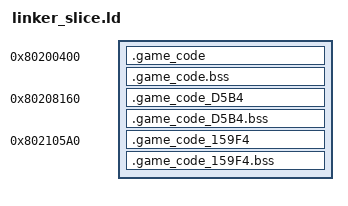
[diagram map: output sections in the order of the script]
/* generated from config.toml; do not edit */
OUTPUT_ARCH(mips)
SECTIONS
{
    .game_code 0x80200400 : AT(0x5854) SUBALIGN(1)
    {
        src/AI/DEVICES/ACTIONHIT/ACTIONHIT.CPP.o(.text);
        . = MAX(., 0x46C);
        src/AI/DEVICES/DAMAGEAI/DAMAGEAI.CPP.o(.text);
        . = MAX(., 0x8AC);
        src/AI/DEVICES/DEVICECALLBACK/DEVICECALLBACK.CPP.o(.text);
        . = MAX(., 0xAEC);
        src/AI/DEVICES/SPAWNAI/SPAWNAI.CPP.o(.text);
        . = MAX(., 0x144C);
        src/AI/DEVICES/MOVINGAI/MOVINGAI.CPP.o(.text);
        . = MAX(., 0x1B38);
        src/AI/DEVICES/MOVINGAI/TRIGGERED_UPDATETRIGGEREDMOTION.CPP.o(.text);
        . = MAX(., 0x2CDC);
        src/AI/DEVICES/PLAYERMATRIX/PLAYERMATRIX.CPP.o(.text);
        . = MAX(., 0x33C4);
        src/AI/DEVICES/ACTIONAI/LEVEL_UPDATEBREAKABLEHIT_PADDING.CPP.o(.data);
        . = MAX(., 0x33CC);
        src/AI/NAV/PLAYER/PLAYER.CPP.o(.text);
        . = MAX(., 0x49C4);
        src/AI/NAV/PLAYER/SCALED_UPDATETARGETPITCH.CPP.o(.text);
        . = MAX(., 0x524C);
        src/AI/NAV/PORTAL/PORTAL_UPDATEALTERNATINGACTIONBURSTS.CPP.o(.text);
        . = MAX(., 0x5DD8);
        src/AI/NAV/PORTAL/PORTAL.CPP.o(.text);
        . = MAX(., 0x6D28);
        src/AI/NAV/PORTAL/PORTAL_SEARCHPATH.CPP.o(.text);
    }
    .game_code.bss (NOLOAD) :
    {
        src/AI/DEVICES/ACTIONHIT/ACTIONHIT.CPP.o(.bss .sbss COMMON);
        src/AI/DEVICES/DAMAGEAI/DAMAGEAI.CPP.o(.bss .sbss COMMON);
        src/AI/DEVICES/DEVICECALLBACK/DEVICECALLBACK.CPP.o(.bss .sbss COMMON);
        src/AI/DEVICES/SPAWNAI/SPAWNAI.CPP.o(.bss .sbss COMMON);
        src/AI/DEVICES/MOVINGAI/MOVINGAI.CPP.o(.bss .sbss COMMON);
        src/AI/DEVICES/MOVINGAI/TRIGGERED_UPDATETRIGGEREDMOTION.CPP.o(.bss .sbss COMMON);
        src/AI/DEVICES/PLAYERMATRIX/PLAYERMATRIX.CPP.o(.bss .sbss COMMON);
        src/AI/DEVICES/ACTIONAI/LEVEL_UPDATEBREAKABLEHIT_PADDING.CPP.o(.bss .sbss COMMON);
        src/AI/NAV/PLAYER/PLAYER.CPP.o(.bss .sbss COMMON);
        src/AI/NAV/PLAYER/SCALED_UPDATETARGETPITCH.CPP.o(.bss .sbss COMMON);
        src/AI/NAV/PORTAL/PORTAL_UPDATEALTERNATINGACTIONBURSTS.CPP.o(.bss .sbss COMMON);
        src/AI/NAV/PORTAL/PORTAL.CPP.o(.bss .sbss COMMON);
        src/AI/NAV/PORTAL/PORTAL_SEARCHPATH.CPP.o(.bss .sbss COMMON);
    }
    .game_code_D5B4 0x80208160 : AT(0xD5B4) SUBALIGN(1)
    {
        src/AI/NAV/PORTAL/PORTAL_ISNODEMOVEMENTBLOCKED.CPP.o(.text);
        . = MAX(., 0x6DC);
        src/AI/NAV/ROUTE/ROUTE.CPP.o(.text);
        . = MAX(., 0x88C);
        src/AI/NAV/SEARCHNODE/SEARCHNODE.CPP.o(.text.Nav_AddGoalNode);
        . = MAX(., 0x8EC);
        src/AI/NAV/SEARCHNODE/SEARCHNODE.CPP.o(.text.Nav_OpenSearchNode);
        . = MAX(., 0x8F8);
        src/AI/NAV/SEARCHNODE/SEARCHNODE.CPP.o(.text.Nav_TakeLowestCostOpenNode);
        . = MAX(., 0x968);
        src/AI/NAV/SEARCHNODE/SEARCHNODE.CPP.o(.text.Nav_CloseSearchNode);
        . = MAX(., 0x974);
        src/AI/NAV/ROUTECOST/ROUTECOST.CPP.o(.text.Nav_IsSearchNodeOpen);
        . = MAX(., 0x984);
        src/AI/NAV/SEARCHNODE/SEARCHNODE.CPP.o(.text.Nav_IsSearchNodeClosed);
        . = MAX(., 0x994);
        src/AI/NAV/SEARCHNODE/SEARCHNODE.CPP.o(.text.Nav_HasOpenSearchNodes);
        . = MAX(., 0x9C8);
        src/AI/NAV/SEARCHNODE/SEARCHNODE.CPP.o(.text.Nav_ClearSearchNodeStatus);
        . = MAX(., 0x9D0);
        src/AI/DEVICES/ACTIONAI/ACTION_LINK_GAP_FRAGMENTS.CPP.o(.data);
        . = MAX(., 0x9DC);
        src/AI/NAV/PICKUP.CPP.o(.text);
        . = MAX(., 0x102C);
        src/AI/NAV/POINTS/POINTS.CPP.o(.text);
        . = MAX(., 0x1270);
        src/AI/DEVICES/PLAYER/DEVICE_BUILDPLAYERMATRIX/DEVICE_BUILDPLAYERMATRIX.CPP.o(.data);
        . = MAX(., 0x127C);
        src/AI/NAV/ATTACK/ATTACK.CPP.o(.text);
        . = MAX(., 0x130C);
        src/AI/NAV/RESELECT/RESELECT.CPP.o(.text);
        . = MAX(., 0x1440);
        src/AI/NAV/RESELECT/RESELECT.CPP.o(.data);
        . = MAX(., 0x144C);
        src/AI/NAV/BALLISTIC/BALLISTIC.CPP.o(.text);
        . = MAX(., 0x2070);
        src/AI/NAV/NAV/G_NAVTRAILINGBYTESBLOCK1.CPP.o(.data);
        . = MAX(., 0x207C);
        src/AI/NAV/TEAMMARKER/TEAMMARKER.CPP.o(.text);
        . = MAX(., 0x214C);
        src/AI/NAV/PICKUPGOAL/PICKUPGOAL.CPP.o(.text);
        . = MAX(., 0x23BC);
        src/AI/NAV/ROUTECOST/ROUTECOST.CPP.o(.text.Nav_UpdateRouteIntermediateGoal);
        . = MAX(., 0x2438);
        src/AI/NAV/ROUTECOST/ROUTECOST.CPP.o(.text.Nav_SetLinkedActorNodeCosts);
        . = MAX(., 0x24BC);
        src/AI/NAV/ROUTECOST/ROUTECOST.CPP.o(.text.Nav_AccumulateNodeTickCosts);
        . = MAX(., 0x2510);
        src/AI/NAV/ROUTECOST/ROUTECOST.CPP.o(.text.Nav_AddPickupCategoryCosts);
        . = MAX(., 0x25C0);
        src/AI/NAV/ROUTECOST/ROUTECOST.CPP.o(.data);
        . = MAX(., 0x25CC);
        src/AI/NAV/PICKUPSELECT/PICKUPSELECT.CPP.o(.text);
        . = MAX(., 0x27BC);
        src/AI/NAV/PICKUPTARGET/PICKUPTARGET.CPP.o(.text);
        . = MAX(., 0x2D24);
        src/AI/NAV/NAV/NAV_TRAILING_BYTES_EU_EU_X_US_US_REV1.CPP.o(.data);
        . = MAX(., 0x2D2C);
        src/AI/NAV/TARGET/TARGET.CPP.o(.text);
        . = MAX(., 0x307C);
        src/AI/NAV/PLAYERSTATE/PLAYERSTATE.CPP.o(.text);
        . = MAX(., 0x341C);
        src/AI/NAV/WEAPONSELECT/WEAPONSELECT.CPP.o(.text);
        . = MAX(., 0x374C);
        src/AI/NAV/RANDOMWEAPON/RANDOMWEAPON.CPP.o(.text);
        . = MAX(., 0x37E4);
        src/AI/NAV/NAV.CPP.o(.data);
        . = MAX(., 0x37EC);
        src/AI/NAV/CLOSEATTACK/CLOSEATTACK.CPP.o(.text);
        . = MAX(., 0x3894);
        src/AI/NAV/NAV_CHECKCLOSEATTACKROUTE/G_NAVCHECKCLOSEATTACKROUTETRAILINGBYTESBLOCK1.CPP.o(.data);
        . = MAX(., 0x389C);
        src/AI/NAV/ATTACKTARGET/ATTACKTARGET.CPP.o(.text);
        . = MAX(., 0x3D48);
        src/DATA/MAINCODE/MAINCODE.CPP.o(.data);
        . = MAX(., 0x3D4C);
        src/AI/NAV/WHEEL/WHEEL.CPP.o(.text);
        . = MAX(., 0x4680);
        src/AI/NAV/NAV_INIT/NAV_INIT.CPP.o(.data);
        . = MAX(., 0x468C);
        src/AI/NAV/BEHAVIOUR/BEHAVIOUR.CPP.o(.text);
        . = MAX(., 0x4788);
        src/AI/NAV/BEHAVIOUR/BEHAVIOUR.CPP.o(.data);
        . = MAX(., 0x478C);
        src/AI/NAV/STRAFE/STRAFE.CPP.o(.text);
        . = MAX(., 0x4ADC);
        src/AI/NAV/COMBAT/COMBAT.CPP.o(.text);
        . = MAX(., 0x5ABC);
        src/AI/NAV/COMBATINIT/COMBATINIT.CPP.o(.text);
        . = MAX(., 0x5CD0);
        src/AI/NAV/ATTACK_TARGET/NAV/G_NAVTRAILINGBYTESBLOCK8.CPP.o(.data);
        . = MAX(., 0x5CDC);
        src/AI/NAV/FARTHEST/FARTHEST.CPP.o(.text);
        . = MAX(., 0x62FC);
        src/AI/NAV/CARRIER/CARRIER.CPP.o(.text);
        . = MAX(., 0x63C4);
        src/AI/NAV/CARRIER/CARRIER.CPP.o(.data);
        . = MAX(., 0x63CC);
        src/AI/NAV/TARGETFOLLOW/TARGETFOLLOW.CPP.o(.text);
        . = MAX(., 0x6470);
        src/AI/NAV/NAV/NAV_ENCODED_WORDS_EU.CPP.o(.data);
        . = MAX(., 0x647C);
        src/AI/NAV/PATROL/PATROL.CPP.o(.text);
        . = MAX(., 0x6640);
        src/AI/NAV/PATROL/PATROL.CPP.o(.data);
        . = MAX(., 0x664C);
        src/AI/NAV/OBJECTCHASE/NAV_UPDATEOBJECTARRIVALCHASE.CPP.o(.text);
        . = MAX(., 0x6844);
        src/AI/NAV/OBJECTCHASE/NAV_UPDATEOBJECTARRIVALCHASE.CPP.o(.data);
        . = MAX(., 0x684C);
        src/AI/NAV/JUMPROUTE/JUMPROUTE.CPP.o(.text);
        . = MAX(., 0x69A8);
        src/AI/NAV/WHEEL/NAV/WHEEL_TRAILING_BYTES_EU_EU_X_US_US_REV1.CPP.o(.data);
        . = MAX(., 0x69AC);
        src/AI/NAV/ROAMGOAL/ROAMGOAL.CPP.o(.text);
        . = MAX(., 0x6B6C);
        src/AI/NAV/ROAM/ROAM.CPP.o(.text);
        . = MAX(., 0x6F54);
        src/AI/NAV/NAV/NAV_UPDATETRANSIENTJUMPROUTE_TRAILINGBYTES.CPP.o(.data);
        . = MAX(., 0x6F5C);
        src/AI/NAV/ACTOR/ACTOR.CPP.o(.text);
        . = MAX(., 0x7364);
        src/AI/NAV/ACTOR/NAV_APPLYSUPPORTINGPLATFORMMOTION.CPP.o(.text);
        . = MAX(., 0x7540);
        src/AI/NAV/ACTOR/ACTOR_UPDATEACTORSTATEANIMATION.CPP.o(.text);
        . = MAX(., 0x797C);
        src/AI/CBARREL/CBARREL_SELECTCOMBATTARGET.CPP.o(.text);
    }
    .game_code_D5B4.bss (NOLOAD) :
    {
        src/AI/NAV/PORTAL/PORTAL_ISNODEMOVEMENTBLOCKED.CPP.o(.bss .sbss COMMON);
        src/AI/NAV/ROUTE/ROUTE.CPP.o(.bss .sbss COMMON);
        src/AI/NAV/SEARCHNODE/SEARCHNODE.CPP.o(.bss .sbss COMMON);
        src/AI/NAV/ROUTECOST/ROUTECOST.CPP.o(.bss .sbss COMMON);
        src/AI/DEVICES/ACTIONAI/ACTION_LINK_GAP_FRAGMENTS.CPP.o(.bss .sbss COMMON);
        src/AI/NAV/PICKUP.CPP.o(.bss .sbss COMMON);
        src/AI/NAV/POINTS/POINTS.CPP.o(.bss .sbss COMMON);
        src/AI/DEVICES/PLAYER/DEVICE_BUILDPLAYERMATRIX/DEVICE_BUILDPLAYERMATRIX.CPP.o(.bss .sbss COMMON);
        src/AI/NAV/ATTACK/ATTACK.CPP.o(.bss .sbss COMMON);
        src/AI/NAV/RESELECT/RESELECT.CPP.o(.bss .sbss COMMON);
        src/AI/NAV/BALLISTIC/BALLISTIC.CPP.o(.bss .sbss COMMON);
        src/AI/NAV/NAV/G_NAVTRAILINGBYTESBLOCK1.CPP.o(.bss .sbss COMMON);
        src/AI/NAV/TEAMMARKER/TEAMMARKER.CPP.o(.bss .sbss COMMON);
        src/AI/NAV/PICKUPGOAL/PICKUPGOAL.CPP.o(.bss .sbss COMMON);
        src/AI/NAV/PICKUPSELECT/PICKUPSELECT.CPP.o(.bss .sbss COMMON);
        src/AI/NAV/PICKUPTARGET/PICKUPTARGET.CPP.o(.bss .sbss COMMON);
        src/AI/NAV/NAV/NAV_TRAILING_BYTES_EU_EU_X_US_US_REV1.CPP.o(.bss .sbss COMMON);
        src/AI/NAV/TARGET/TARGET.CPP.o(.bss .sbss COMMON);
        src/AI/NAV/PLAYERSTATE/PLAYERSTATE.CPP.o(.bss .sbss COMMON);
        src/AI/NAV/WEAPONSELECT/WEAPONSELECT.CPP.o(.bss .sbss COMMON);
        src/AI/NAV/RANDOMWEAPON/RANDOMWEAPON.CPP.o(.bss .sbss COMMON);
        src/AI/NAV/NAV.CPP.o(.bss .sbss COMMON);
        src/AI/NAV/CLOSEATTACK/CLOSEATTACK.CPP.o(.bss .sbss COMMON);
        src/AI/NAV/NAV_CHECKCLOSEATTACKROUTE/G_NAVCHECKCLOSEATTACKROUTETRAILINGBYTESBLOCK1.CPP.o(.bss .sbss COMMON);
        src/AI/NAV/ATTACKTARGET/ATTACKTARGET.CPP.o(.bss .sbss COMMON);
        src/DATA/MAINCODE/MAINCODE.CPP.o(.bss .sbss COMMON);
        src/AI/NAV/WHEEL/WHEEL.CPP.o(.bss .sbss COMMON);
        src/AI/NAV/NAV_INIT/NAV_INIT.CPP.o(.bss .sbss COMMON);
        src/AI/NAV/BEHAVIOUR/BEHAVIOUR.CPP.o(.bss .sbss COMMON);
        src/AI/NAV/STRAFE/STRAFE.CPP.o(.bss .sbss COMMON);
        src/AI/NAV/COMBAT/COMBAT.CPP.o(.bss .sbss COMMON);
        src/AI/NAV/COMBATINIT/COMBATINIT.CPP.o(.bss .sbss COMMON);
        src/AI/NAV/ATTACK_TARGET/NAV/G_NAVTRAILINGBYTESBLOCK8.CPP.o(.bss .sbss COMMON);
        src/AI/NAV/FARTHEST/FARTHEST.CPP.o(.bss .sbss COMMON);
        src/AI/NAV/CARRIER/CARRIER.CPP.o(.bss .sbss COMMON);
        src/AI/NAV/TARGETFOLLOW/TARGETFOLLOW.CPP.o(.bss .sbss COMMON);
        src/AI/NAV/NAV/NAV_ENCODED_WORDS_EU.CPP.o(.bss .sbss COMMON);
        src/AI/NAV/PATROL/PATROL.CPP.o(.bss .sbss COMMON);
        src/AI/NAV/OBJECTCHASE/NAV_UPDATEOBJECTARRIVALCHASE.CPP.o(.bss .sbss COMMON);
        src/AI/NAV/JUMPROUTE/JUMPROUTE.CPP.o(.bss .sbss COMMON);
        src/AI/NAV/WHEEL/NAV/WHEEL_TRAILING_BYTES_EU_EU_X_US_US_REV1.CPP.o(.bss .sbss COMMON);
        src/AI/NAV/ROAMGOAL/ROAMGOAL.CPP.o(.bss .sbss COMMON);
        src/AI/NAV/ROAM/ROAM.CPP.o(.bss .sbss COMMON);
        src/AI/NAV/NAV/NAV_UPDATETRANSIENTJUMPROUTE_TRAILINGBYTES.CPP.o(.bss .sbss COMMON);
        src/AI/NAV/ACTOR/ACTOR.CPP.o(.bss .sbss COMMON);
        src/AI/NAV/ACTOR/NAV_APPLYSUPPORTINGPLATFORMMOTION.CPP.o(.bss .sbss COMMON);
        src/AI/NAV/ACTOR/ACTOR_UPDATEACTORSTATEANIMATION.CPP.o(.bss .sbss COMMON);
        src/AI/CBARREL/CBARREL_SELECTCOMBATTARGET.CPP.o(.bss .sbss COMMON);
    }
    .game_code_159F4 0x802105A0 : AT(0x159F4) SUBALIGN(1)
    {
        src/AI/CBARREL/CBARREL_RESOLVETRACKGOAL.CPP.o(.text);
        . = MAX(., 0x63C);
        src/AI/CBARREL/BARREL_GETFACINGSIDE.CPP.o(.text);
        . = MAX(., 0x1334);
        src/AI/CBARREL/BARREL_GETIMPACTSLOT.CPP.o(.text);
        . = MAX(., 0x14B4);
        src/AI/CBARREL/BARREL_SPAWNACTOREFFECT.CPP.o(.text);
        . = MAX(., 0x1920);
        src/AI/CBARREL/CBARREL_SELECTWEIGHTEDANIMATION.CPP.o(.text);
        . = MAX(., 0x1A34);
        src/AI/CBARREL/BARREL_APPLYCLAMPEDTURN.CPP.o(.text);
        . = MAX(., 0x1AE4);
        src/AI/CBARREL/CBARREL_TURNTOWARDCLEARAIM.CPP.o(.text);
        . = MAX(., 0x1BD8);
        src/AI/CBARREL/CBARREL_CLASSIFYTRACKTARGET.CPP.o(.text);
        . = MAX(., 0x1C98);
        src/AI/CBARREL/CBARREL_TESTFLAGGEDAIMOBSTRUCTION.CPP.o(.text);
        . = MAX(., 0x1E20);
        src/AI/CBARREL/CBARREL_TESTTARGETEYEOBSTRUCTION.CPP.o(.text);
        . = MAX(., 0x1F5C);
        src/AI/CBARREL/CBARREL_LOCKTRACKERTARGET.CPP.o(.text);
        . = MAX(., 0x1F68);
        src/AI/CBARREL/BARREL_UPDATETRACKGOALS.CPP.o(.text);
        . = MAX(., 0x2170);
        src/AI/CBARREL/BARREL_GETSIGNEDANGLETOPOINT.CPP.o(.text);
        . = MAX(., 0x22A0);
        src/AI/CBARREL/BARREL_SPAWNFLAGGEDEFFECTS.CPP.o(.text);
        . = MAX(., 0x2858);
        src/AI/CTEAMSELECT/CTEAMSELECT/CTEAMSELECT.CPP.o(.data);
        . = MAX(., 0x285C);
        src/AI/CTEAMSELECT/CTEAMSELECT.CPP.o(.text);
        . = MAX(., 0x37FC);
        src/AI/CTEAMSELECT/CTEAMSELECT_DRAWTEAMICONS.CPP.o(.text);
        . = MAX(., 0x3DB0);
        src/AI/CTEAMSELECT/CTEAMSELECT_UPDATETEAMWHEEL.CPP.o(.text);
        . = MAX(., 0x40F4);
        src/AI/CTEAMSELECT/PLAYER_RESETPLAYERFORROUND_DATA.CPP.o(.text);
        . = MAX(., 0x41F8);
        src/AI/CTEAMSELECT/CTEAMSELECT_DRAWTEAMWHEEL.CPP.o(.text);
        . = MAX(., 0x4380);
        src/AI/CTEAMSELECT/CTEAMSELECT_INITTEAMCHOICES.CPP.o(.text);
        . = MAX(., 0x43D8);
        src/AI/CTEAMSELECT/CTEAMSELECT_UPDATETEAMCHOICEINPUT.CPP.o(.text);
        . = MAX(., 0x4510);
        src/AI/NAV/NAV_FOLLOWMARKERCARRIERROUTE/NAV_FOLLOWMARKERCARRIERROUTE.CPP.o(.data);
        . = MAX(., 0x451C);
        src/AI/PLAYERAI/PLAYERAI.CPP.o(.text);
        . = MAX(., 0x670C);
        src/AI/PLAYER/PLAYER_DEATH.CPP.o(.text);
        . = MAX(., 0x7940);
        src/AI/PLAYER/PLAYER_DRAWREDMARKERPRISM.CPP.o(.text);
        . = MAX(., 0x7C80);
        src/AI/PLAYER/PLAYER_MODEL_AND_HELD_WEAPON_RENDERING.CPP.o(.text);
        . = MAX(., 0x803C);
        src/AI/PLAYER/PLAYERAI_COMPUTEAIMROTATION.CPP.o(.text);
        . = MAX(., 0x86B0);
        src/AI/PLAYER/PLAYER_AIM_MARKER_MATRICES.CPP.o(.text);
        . = MAX(., 0x8A1C);
        src/AI/PLAYER/PLAYERAI_UPDATEAIMANDLOCKMARKER.CPP.o(.text);
        . = MAX(., 0x9334);
        src/AI/PLAYER/PLAYER_UPDATEPLAYEREFFECTLIGHTS_DATA.CPP.o(.text);
        . = MAX(., 0x9548);
        src/AI/PLAYER/PLAYER_UPDATEPLAYEREFFECTLIGHTS.CPP.o(.text);
        . = MAX(., 0x9CFC);
        src/AI/PLAYER/PLAYERAI_DRAWAMMOCOUNTERS.CPP.o(.text);
        . = MAX(., 0xA1A4);
        src/AI/PLAYER_UPDATEPLAYERCAMERA/PLAYER_UPDATEPLAYERCAMERA.CPP.o(.text);
        . = MAX(., 0xF344);
        src/AI/PLAYER/PLAYER_FLY_AND_STANDING_STATES.CPP.o(.text);
        . = MAX(., 0xF9B4);
        src/AI/PLAYER/PLAYERAI_UPDATEWALKINGMOVEMENT.CPP.o(.text);
        . = MAX(., 0xFEF4);
        src/AI/PLAYER/PLAYER_WADING_STATE.CPP.o(.text);
        . = MAX(., 0x10204);
        src/AI/PLAYER/PLAYER_UPDATEFLOATINGSTATE.CPP.o(.text);
        . = MAX(., 0x10484);
        src/AI/PLAYER/PLAYER_UPDATESWIMMINGSTATE.CPP.o(.text);
        . = MAX(., 0x10BE8);
        src/AI/PLAYER/PLAYERAI_RESETPLAYERAFTERDEATH.CPP.o(.text);
        . = MAX(., 0x10FDC);
        src/AI/PLAYER/PLAYERAI_ENTERMOVINGSEQUENCESTATE_DATA.CPP.o(.text);
        . = MAX(., 0x115E8);
        src/AI/PLAYER/PLAYERAI_INITIALIZEPLAYERHEALTH.CPP.o(.text);
        . = MAX(., 0x11BF8);
        src/AI/PLAYER/PLAYER_BUILDPLAYERVIEWTRANSFORM.CPP.o(.text);
        . = MAX(., 0x122E0);
        src/AI/PLAYERAI/PLAYER_UPDATEFRAGTAGSELECTION.CPP.o(.text);
        . = MAX(., 0x143E0);
        src/AI/PLAYERAI/PLAYER_DRAWTINTEDPLAYER.CPP.o(.text);
        . = MAX(., 0x14C3C);
        src/AI/PLAYER/PLAYERAI_APPLYSTUN.CPP.o(.text);
        . = MAX(., 0x14EA0);
        src/AI/PLAYER/PLAYERAI_FINDTRANSIENTPLAYER.CPP.o(.text);
    }
    .game_code_159F4.bss (NOLOAD) :
    {
        src/AI/CBARREL/CBARREL_RESOLVETRACKGOAL.CPP.o(.bss .sbss COMMON);
        src/AI/CBARREL/BARREL_GETFACINGSIDE.CPP.o(.bss .sbss COMMON);
        src/AI/CBARREL/BARREL_GETIMPACTSLOT.CPP.o(.bss .sbss COMMON);
        src/AI/CBARREL/BARREL_SPAWNACTOREFFECT.CPP.o(.bss .sbss COMMON);
        src/AI/CBARREL/CBARREL_SELECTWEIGHTEDANIMATION.CPP.o(.bss .sbss COMMON);
        src/AI/CBARREL/BARREL_APPLYCLAMPEDTURN.CPP.o(.bss .sbss COMMON);
        src/AI/CBARREL/CBARREL_TURNTOWARDCLEARAIM.CPP.o(.bss .sbss COMMON);
        src/AI/CBARREL/CBARREL_CLASSIFYTRACKTARGET.CPP.o(.bss .sbss COMMON);
        src/AI/CBARREL/CBARREL_TESTFLAGGEDAIMOBSTRUCTION.CPP.o(.bss .sbss COMMON);
        src/AI/CBARREL/CBARREL_TESTTARGETEYEOBSTRUCTION.CPP.o(.bss .sbss COMMON);
        src/AI/CBARREL/CBARREL_LOCKTRACKERTARGET.CPP.o(.bss .sbss COMMON);
        src/AI/CBARREL/BARREL_UPDATETRACKGOALS.CPP.o(.bss .sbss COMMON);
        src/AI/CBARREL/BARREL_GETSIGNEDANGLETOPOINT.CPP.o(.bss .sbss COMMON);
        src/AI/CBARREL/BARREL_SPAWNFLAGGEDEFFECTS.CPP.o(.bss .sbss COMMON);
        src/AI/CTEAMSELECT/CTEAMSELECT/CTEAMSELECT.CPP.o(.bss .sbss COMMON);
        src/AI/CTEAMSELECT/CTEAMSELECT.CPP.o(.bss .sbss COMMON);
        src/AI/CTEAMSELECT/CTEAMSELECT_DRAWTEAMICONS.CPP.o(.bss .sbss COMMON);
        src/AI/CTEAMSELECT/CTEAMSELECT_UPDATETEAMWHEEL.CPP.o(.bss .sbss COMMON);
        src/AI/CTEAMSELECT/PLAYER_RESETPLAYERFORROUND_DATA.CPP.o(.bss .sbss COMMON);
        src/AI/CTEAMSELECT/CTEAMSELECT_DRAWTEAMWHEEL.CPP.o(.bss .sbss COMMON);
        src/AI/CTEAMSELECT/CTEAMSELECT_INITTEAMCHOICES.CPP.o(.bss .sbss COMMON);
        src/AI/CTEAMSELECT/CTEAMSELECT_UPDATETEAMCHOICEINPUT.CPP.o(.bss .sbss COMMON);
        src/AI/NAV/NAV_FOLLOWMARKERCARRIERROUTE/NAV_FOLLOWMARKERCARRIERROUTE.CPP.o(.bss .sbss COMMON);
        src/AI/PLAYERAI/PLAYERAI.CPP.o(.bss .sbss COMMON);
        src/AI/PLAYER/PLAYER_DEATH.CPP.o(.bss .sbss COMMON);
        src/AI/PLAYER/PLAYER_DRAWREDMARKERPRISM.CPP.o(.bss .sbss COMMON);
        src/AI/PLAYER/PLAYER_MODEL_AND_HELD_WEAPON_RENDERING.CPP.o(.bss .sbss COMMON);
        src/AI/PLAYER/PLAYERAI_COMPUTEAIMROTATION.CPP.o(.bss .sbss COMMON);
        src/AI/PLAYER/PLAYER_AIM_MARKER_MATRICES.CPP.o(.bss .sbss COMMON);
        src/AI/PLAYER/PLAYERAI_UPDATEAIMANDLOCKMARKER.CPP.o(.bss .sbss COMMON);
        src/AI/PLAYER/PLAYER_UPDATEPLAYEREFFECTLIGHTS_DATA.CPP.o(.bss .sbss COMMON);
        src/AI/PLAYER/PLAYER_UPDATEPLAYEREFFECTLIGHTS.CPP.o(.bss .sbss COMMON);
        src/AI/PLAYER/PLAYERAI_DRAWAMMOCOUNTERS.CPP.o(.bss .sbss COMMON);
        src/AI/PLAYER_UPDATEPLAYERCAMERA/PLAYER_UPDATEPLAYERCAMERA.CPP.o(.bss .sbss COMMON);
        src/AI/PLAYER/PLAYER_FLY_AND_STANDING_STATES.CPP.o(.bss .sbss COMMON);
        src/AI/PLAYER/PLAYERAI_UPDATEWALKINGMOVEMENT.CPP.o(.bss .sbss COMMON);
        src/AI/PLAYER/PLAYER_WADING_STATE.CPP.o(.bss .sbss COMMON);
        src/AI/PLAYER/PLAYER_UPDATEFLOATINGSTATE.CPP.o(.bss .sbss COMMON);
        src/AI/PLAYER/PLAYER_UPDATESWIMMINGSTATE.CPP.o(.bss .sbss COMMON);
        src/AI/PLAYER/PLAYERAI_RESETPLAYERAFTERDEATH.CPP.o(.bss .sbss COMMON);
        src/AI/PLAYER/PLAYERAI_ENTERMOVINGSEQUENCESTATE_DATA.CPP.o(.bss .sbss COMMON);
        src/AI/PLAYER/PLAYERAI_INITIALIZEPLAYERHEALTH.CPP.o(.bss .sbss COMMON);
        src/AI/PLAYER/PLAYER_BUILDPLAYERVIEWTRANSFORM.CPP.o(.bss .sbss COMMON);
        src/AI/PLAYERAI/PLAYER_UPDATEFRAGTAGSELECTION.CPP.o(.bss .sbss COMMON);
        src/AI/PLAYERAI/PLAYER_DRAWTINTEDPLAYER.CPP.o(.bss .sbss COMMON);
        src/AI/PLAYER/PLAYERAI_APPLYSTUN.CPP.o(.bss .sbss COMMON);
        src/AI/PLAYER/PLAYERAI_FINDTRANSIENTPLAYER.CPP.o(.bss .sbss COMMON);
    }
    /DISCARD/ : { *(.MIPS.abiflags .reginfo .pdr .mdebug* .options .debug* .comment .note* .gnu.attributes) }
}
INCLUDE undefined_syms.ld
